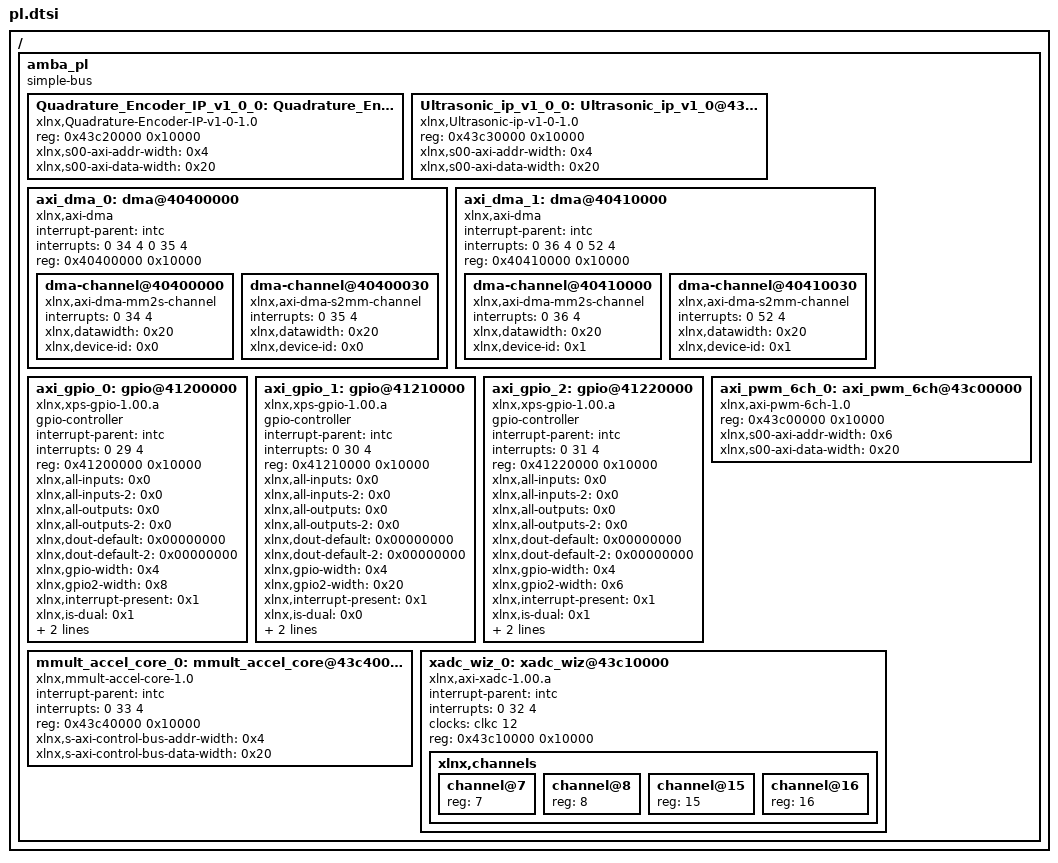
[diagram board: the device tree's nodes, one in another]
/*
 * CAUTION: This file is automatically generated by Xilinx.
 * Version:  
 * Today is: Sun Aug 30 11:31:46 2015
*/
/include/ "zynq-7000.dtsi"

/ {
	amba_pl: amba_pl {
		#address-cells = <1>;
		#size-cells = <1>;
		compatible = "simple-bus";
		ranges ;
		Quadrature_Encoder_IP_v1_0_0: Quadrature_Encoder_IP_v1_0@43c20000 {
			compatible = "xlnx,Quadrature-Encoder-IP-v1-0-1.0";
			reg = <0x43c20000 0x10000>;
			xlnx,s00-axi-addr-width = <0x4>;
			xlnx,s00-axi-data-width = <0x20>;
		};
		Ultrasonic_ip_v1_0_0: Ultrasonic_ip_v1_0@43c30000 {
			compatible = "xlnx,Ultrasonic-ip-v1-0-1.0";
			reg = <0x43c30000 0x10000>;
			xlnx,s00-axi-addr-width = <0x4>;
			xlnx,s00-axi-data-width = <0x20>;
		};
		axi_dma_0: dma@40400000 {
			compatible = "xlnx,axi-dma";
			interrupt-parent = <&intc>;
			interrupts = <0 34 4 0 35 4>;
			reg = <0x40400000 0x10000>;
			dma-channel@40400000 {
				compatible = "xlnx,axi-dma-mm2s-channel";
				interrupts = <0 34 4>;
				xlnx,datawidth = <0x20>;
				xlnx,device-id = <0x0>;
			};
			dma-channel@40400030 {
				compatible = "xlnx,axi-dma-s2mm-channel";
				interrupts = <0 35 4>;
				xlnx,datawidth = <0x20>;
				xlnx,device-id = <0x0>;
			};
		};
		axi_dma_1: dma@40410000 {
			compatible = "xlnx,axi-dma";
			interrupt-parent = <&intc>;
			interrupts = <0 36 4 0 52 4>;
			reg = <0x40410000 0x10000>;
			dma-channel@40410000 {
				compatible = "xlnx,axi-dma-mm2s-channel";
				interrupts = <0 36 4>;
				xlnx,datawidth = <0x20>;
				xlnx,device-id = <0x1>;
			};
			dma-channel@40410030 {
				compatible = "xlnx,axi-dma-s2mm-channel";
				interrupts = <0 52 4>;
				xlnx,datawidth = <0x20>;
				xlnx,device-id = <0x1>;
			};
		};
		axi_gpio_0: gpio@41200000 {
			#gpio-cells = <2>;
			compatible = "xlnx,xps-gpio-1.00.a";
			gpio-controller ;
			interrupt-parent = <&intc>;
			interrupts = <0 29 4>;
			reg = <0x41200000 0x10000>;
			xlnx,all-inputs = <0x0>;
			xlnx,all-inputs-2 = <0x0>;
			xlnx,all-outputs = <0x0>;
			xlnx,all-outputs-2 = <0x0>;
			xlnx,dout-default = <0x00000000>;
			xlnx,dout-default-2 = <0x00000000>;
			xlnx,gpio-width = <0x4>;
			xlnx,gpio2-width = <0x8>;
			xlnx,interrupt-present = <0x1>;
			xlnx,is-dual = <0x1>;
			xlnx,tri-default = <0xFFFFFFFF>;
			xlnx,tri-default-2 = <0xFFFFFFFF>;
		};
		axi_gpio_1: gpio@41210000 {
			#gpio-cells = <2>;
			compatible = "xlnx,xps-gpio-1.00.a";
			gpio-controller ;
			interrupt-parent = <&intc>;
			interrupts = <0 30 4>;
			reg = <0x41210000 0x10000>;
			xlnx,all-inputs = <0x0>;
			xlnx,all-inputs-2 = <0x0>;
			xlnx,all-outputs = <0x0>;
			xlnx,all-outputs-2 = <0x0>;
			xlnx,dout-default = <0x00000000>;
			xlnx,dout-default-2 = <0x00000000>;
			xlnx,gpio-width = <0x4>;
			xlnx,gpio2-width = <0x20>;
			xlnx,interrupt-present = <0x1>;
			xlnx,is-dual = <0x0>;
			xlnx,tri-default = <0xFFFFFFFF>;
			xlnx,tri-default-2 = <0xFFFFFFFF>;
		};
		axi_gpio_2: gpio@41220000 {
			#gpio-cells = <2>;
			compatible = "xlnx,xps-gpio-1.00.a";
			gpio-controller ;
			interrupt-parent = <&intc>;
			interrupts = <0 31 4>;
			reg = <0x41220000 0x10000>;
			xlnx,all-inputs = <0x0>;
			xlnx,all-inputs-2 = <0x0>;
			xlnx,all-outputs = <0x0>;
			xlnx,all-outputs-2 = <0x0>;
			xlnx,dout-default = <0x00000000>;
			xlnx,dout-default-2 = <0x00000000>;
			xlnx,gpio-width = <0x4>;
			xlnx,gpio2-width = <0x6>;
			xlnx,interrupt-present = <0x1>;
			xlnx,is-dual = <0x1>;
			xlnx,tri-default = <0xFFFFFFFF>;
			xlnx,tri-default-2 = <0xFFFFFFFF>;
		};
		axi_pwm_6ch_0: axi_pwm_6ch@43c00000 {
			compatible = "xlnx,axi-pwm-6ch-1.0";
			reg = <0x43c00000 0x10000>;
			xlnx,s00-axi-addr-width = <0x6>;
			xlnx,s00-axi-data-width = <0x20>;
		};
		mmult_accel_core_0: mmult_accel_core@43c40000 {
			compatible = "xlnx,mmult-accel-core-1.0";
			interrupt-parent = <&intc>;
			interrupts = <0 33 4>;
			reg = <0x43c40000 0x10000>;
			xlnx,s-axi-control-bus-addr-width = <0x4>;
			xlnx,s-axi-control-bus-data-width = <0x20>;
		};
        xadc_wiz_0: xadc_wiz@43c10000 {
            compatible = "xlnx,axi-xadc-1.00.a";
            interrupt-parent = <&intc>;
            interrupts = <0 32 4>;
            clocks = <&clkc 12>;
            reg = <0x43c10000 0x10000>;
            xlnx,channels {
                #address-cells = <1>;
                #size-cells = <0>;
                channel@7 {
                    reg = <7>;
                };
                channel@8 {
                    reg = <8>;
                };
                channel@15 {
                    reg = <15>;
                };
                channel@16 {
                    reg = <16>;
                };
            };
        };
	};
};
